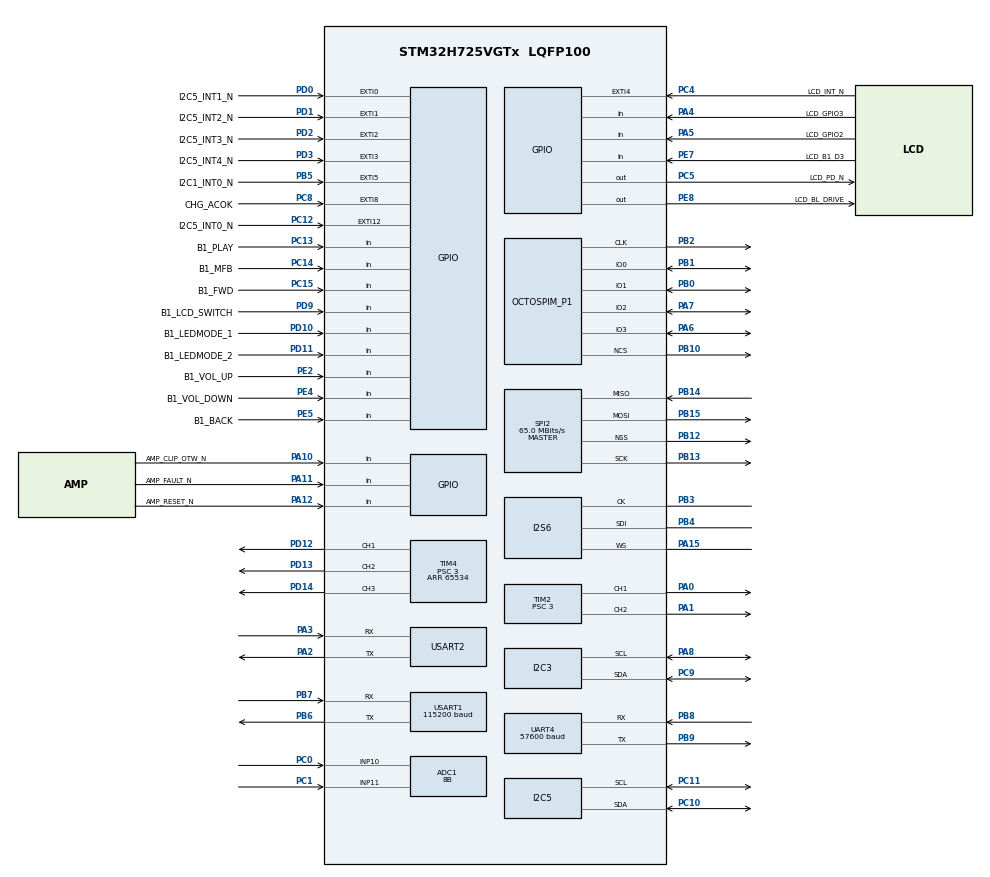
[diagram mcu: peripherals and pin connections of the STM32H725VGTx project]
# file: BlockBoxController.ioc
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ADC1.Channel-0\#ChannelRegularConversion=ADC_CHANNEL_10
ADC1.NbrOfConversion=1
ADC1.NbrOfConversionFlag=1
ADC1.OffsetNumber-0\#ChannelRegularConversion=ADC_OFFSET_NONE
ADC1.OffsetSignedSaturation-0\#ChannelRegularConversion=DISABLE
ADC1.OversamplingMode=ENABLE
ADC1.Rank-0\#ChannelRegularConversion=1
ADC1.Ratio=256
ADC1.Resolution=ADC_RESOLUTION_8B
ADC1.SamplingTime-0\#ChannelRegularConversion=ADC_SAMPLETIME_64CYCLES_5
ADC1.master=1
CORTEX_M7.AccessPermission-Cortex_Memory_Protection_Unit_Region0_Settings=MPU_REGION_FULL_ACCESS
CORTEX_M7.AccessPermission-Cortex_Memory_Protection_Unit_Region1_Settings=MPU_REGION_FULL_ACCESS
CORTEX_M7.AccessPermission-Cortex_Memory_Protection_Unit_Region2_Settings=MPU_REGION_FULL_ACCESS
CORTEX_M7.AccessPermission-Cortex_Memory_Protection_Unit_Region3_Settings=MPU_REGION_PRIV_RO_URO
CORTEX_M7.AccessPermission-Cortex_Memory_Protection_Unit_Region5_Settings=MPU_REGION_FULL_ACCESS
CORTEX_M7.BaseAddress-Cortex_Memory_Protection_Unit_Region1_Settings=0x90000000
CORTEX_M7.BaseAddress-Cortex_Memory_Protection_Unit_Region5_Settings=0x40000000
CORTEX_M7.CPU_ICache=Enabled
CORTEX_M7.DisableExec-Cortex_Memory_Protection_Unit_Region1_Settings=MPU_INSTRUCTION_ACCESS_DISABLE
CORTEX_M7.DisableExec-Cortex_Memory_Protection_Unit_Region4_Settings=MPU_INSTRUCTION_ACCESS_DISABLE
CORTEX_M7.DisableExec-Cortex_Memory_Protection_Unit_Region5_Settings=MPU_INSTRUCTION_ACCESS_DISABLE
CORTEX_M7.Enable-Cortex_Memory_Protection_Unit_Region0_Settings=MPU_REGION_ENABLE
CORTEX_M7.Enable-Cortex_Memory_Protection_Unit_Region1_Settings=MPU_REGION_ENABLE
CORTEX_M7.Enable-Cortex_Memory_Protection_Unit_Region2_Settings=MPU_REGION_ENABLE
CORTEX_M7.Enable-Cortex_Memory_Protection_Unit_Region3_Settings=MPU_REGION_ENABLE
CORTEX_M7.Enable-Cortex_Memory_Protection_Unit_Region4_Settings=MPU_REGION_ENABLE
CORTEX_M7.Enable-Cortex_Memory_Protection_Unit_Region5_Settings=MPU_REGION_ENABLE
CORTEX_M7.IsCacheable-Cortex_Memory_Protection_Unit_Region2_Settings=MPU_ACCESS_CACHEABLE
CORTEX_M7.IsCacheable-Cortex_Memory_Protection_Unit_Region3_Settings=MPU_ACCESS_CACHEABLE
CORTEX_M7.MPU_Control=MPU_PRIVILEGED_DEFAULT
CORTEX_M7.Size-Cortex_Memory_Protection_Unit_Region0_Settings=MPU_REGION_SIZE_4GB
CORTEX_M7.Size-Cortex_Memory_Protection_Unit_Region1_Settings=MPU_REGION_SIZE_256MB
CORTEX_M7.Size-Cortex_Memory_Protection_Unit_Region2_Settings=MPU_REGION_SIZE_512MB
CORTEX_M7.Size-Cortex_Memory_Protection_Unit_Region3_Settings=MPU_REGION_SIZE_64KB
CORTEX_M7.Size-Cortex_Memory_Protection_Unit_Region4_Settings=MPU_REGION_SIZE_4KB
CORTEX_M7.Size-Cortex_Memory_Protection_Unit_Region5_Settings=MPU_REGION_SIZE_512MB
CORTEX_M7.TypeExtField-Cortex_Memory_Protection_Unit_Region0_Settings=MPU_TEX_LEVEL1
CORTEX_M7.TypeExtField-Cortex_Memory_Protection_Unit_Region1_Settings=MPU_TEX_LEVEL2
CORTEX_M7.TypeExtField-Cortex_Memory_Protection_Unit_Region5_Settings=MPU_TEX_LEVEL2
I2C3.Timing=0x2000090E
I2C5.Timing=0x2000090E
I2S6.AudioFreq=I2S_AUDIOFREQ_96K
I2S6.DataFormat=I2S_DATAFORMAT_16B_EXTENDED
I2S6.ErrorAudioFreq=0.0 %
I2S6.Instance=SPI$Index
I2S6.RealAudioFreq=96.0 KHz
IWDG1.Prescaler=IWDG_PRESCALER_8
Mcu.Family=STM32H7
Mcu.Name=STM32H725VGTx
Mcu.Package=LQFP100
NVIC.ADC_IRQn=true\:13\:0\:true\:false\:true\:true\:true\:true
NVIC.EXTI0_IRQn=true\:6\:0\:true\:false\:true\:true\:true\:true
NVIC.EXTI15_10_IRQn=true\:10\:0\:true\:false\:true\:true\:true\:true
NVIC.EXTI1_IRQn=true\:7\:0\:true\:false\:true\:true\:true\:true
NVIC.EXTI2_IRQn=true\:8\:0\:true\:false\:true\:true\:true\:true
NVIC.EXTI3_IRQn=true\:9\:0\:true\:false\:true\:true\:true\:true
NVIC.I2C3_ER_IRQn=true\:13\:0\:true\:false\:true\:true\:true\:true
NVIC.I2C3_EV_IRQn=true\:13\:0\:true\:false\:true\:true\:true\:true
NVIC.I2C5_ER_IRQn=true\:12\:0\:true\:false\:true\:true\:true\:true
NVIC.I2C5_EV_IRQn=true\:12\:0\:true\:false\:true\:true\:true\:true
NVIC.PriorityGroup=NVIC_PRIORITYGROUP_4
NVIC.UART4_IRQn=true\:11\:0\:true\:false\:true\:true\:true\:true
NVIC.USART1_IRQn=true\:12\:0\:true\:false\:true\:true\:true\:true
NVIC.USART2_IRQn=true\:14\:0\:true\:false\:true\:true\:true\:true
OCTOSPI1.ChipSelectHighTime=8
OCTOSPI1.ClockPrescaler=26
OCTOSPI1.DeviceSize=24
OCTOSPI1.MemoryType=HAL_OSPI_MEMTYPE_APMEMORY
PA0.GPIO_PuPd=GPIO_PULLDOWN
PA0.Signal=S_TIM2_CH1_ETR
PA1.GPIO_PuPd=GPIO_PULLDOWN
PA1.Signal=S_TIM2_CH2
PA10.GPIO_Label=AMP_CLIP_OTW_N
PA10.GPIO_PuPd=GPIO_PULLUP
PA10.Signal=GPIO_Input
PA11.GPIO_Label=AMP_FAULT_N
PA11.GPIO_PuPd=GPIO_PULLUP
PA11.Signal=GPIO_Input
PA12.GPIO_Label=AMP_RESET_N
PA12.GPIO_PuPd=GPIO_PULLUP
PA12.Signal=GPIO_Input
PA13(JTMS/SWDIO).Mode=Serial_Wire
PA13(JTMS/SWDIO).Signal=DEBUG_JTMS-SWDIO
PA14(JTCK/SWCLK).Mode=Serial_Wire
PA14(JTCK/SWCLK).Signal=DEBUG_JTCK-SWCLK
PA15(JTDI).Mode=Half_Duplex_Slave_Rx
PA15(JTDI).Signal=I2S6_WS
PA2.Mode=Asynchronous
PA2.Signal=USART2_TX
PA3.Mode=Asynchronous
PA3.Signal=USART2_RX
PA4.GPIO_Label=LCD_GPIO3
PA4.GPIO_PuPd=GPIO_PULLDOWN
PA4.Signal=GPIO_Input
PA5.GPIO_Label=LCD_GPIO2
PA5.GPIO_PuPd=GPIO_PULLDOWN
PA5.Signal=GPIO_Input
PA6.GPIO_PuPd=GPIO_PULLUP
PA6.Mode=OCTOSPI1_IOL_Port1L
PA6.Signal=OCTOSPIM_P1_IO3
PA7.GPIO_PuPd=GPIO_PULLUP
PA7.Mode=OCTOSPI1_IOL_Port1L
PA7.Signal=OCTOSPIM_P1_IO2
PA8.Mode=I2C
PA8.Signal=I2C3_SCL
PB0.GPIO_PuPd=GPIO_PULLUP
PB0.Mode=OCTOSPI1_IOL_Port1L
PB0.Signal=OCTOSPIM_P1_IO1
PB1.GPIO_PuPd=GPIO_PULLUP
PB1.Mode=OCTOSPI1_IOL_Port1L
PB1.Signal=OCTOSPIM_P1_IO0
PB10.Mode=OCTOSPI1_Port1_NCS
PB10.Signal=OCTOSPIM_P1_NCS
PB12.GPIO_Speed=GPIO_SPEED_FREQ_HIGH
PB12.Mode=NSS_Signal_Hard_Output
PB12.Signal=SPI2_NSS
PB13.GPIO_Speed=GPIO_SPEED_FREQ_HIGH
PB13.Mode=Full_Duplex_Master
PB13.Signal=SPI2_SCK
PB14.GPIO_Speed=GPIO_SPEED_FREQ_HIGH
PB14.Mode=Full_Duplex_Master
PB14.Signal=SPI2_MISO
PB15.GPIO_Speed=GPIO_SPEED_FREQ_HIGH
PB15.Mode=Full_Duplex_Master
PB15.Signal=SPI2_MOSI
PB2.Mode=O1_P1_CLK
PB2.Signal=OCTOSPIM_P1_CLK
PB3(JTDO/TRACESWO).Mode=Half_Duplex_Slave_Rx
PB3(JTDO/TRACESWO).Signal=I2S6_CK
PB4(NJTRST).Mode=Half_Duplex_Slave_Rx
PB4(NJTRST).Signal=I2S6_SDI
PB5.GPIO_Label=I2C1_INT0_N
PB5.GPIO_ModeDefaultEXTI=GPIO_MODE_IT_FALLING
PB5.GPIO_PuPd=GPIO_PULLUP
PB5.Signal=GPXTI5
PB6.Mode=Asynchronous
PB6.Signal=USART1_TX
PB7.Mode=Asynchronous
PB7.Signal=USART1_RX
PB8.Mode=Asynchronous
PB8.Signal=UART4_RX
PB9.Mode=Asynchronous
PB9.Signal=UART4_TX
PC0.Signal=ADCx_INP10
PC1.Signal=ADCx_INP11
PC10.Mode=I2C
PC10.Signal=I2C5_SDA
PC11.Mode=I2C
PC11.Signal=I2C5_SCL
PC12.GPIO_Label=I2C5_INT0_N
PC12.GPIO_ModeDefaultEXTI=GPIO_MODE_IT_FALLING
PC12.GPIO_PuPd=GPIO_PULLUP
PC12.Signal=GPXTI12
PC13.GPIO_Label=B1_PLAY
PC13.GPIO_PuPd=GPIO_PULLUP
PC13.Signal=GPIO_Input
PC14-OSC32_IN.GPIO_Label=B1_MFB
PC14-OSC32_IN.GPIO_PuPd=GPIO_PULLUP
PC14-OSC32_IN.Signal=GPIO_Input
PC15-OSC32_OUT.GPIO_Label=B1_FWD
PC15-OSC32_OUT.GPIO_PuPd=GPIO_PULLUP
PC15-OSC32_OUT.Signal=GPIO_Input
PC4.GPIO_Label=LCD_INT_N
PC4.GPIO_ModeDefaultEXTI=GPIO_MODE_IT_FALLING
PC4.GPIO_PuPd=GPIO_PULLUP
PC4.Signal=GPXTI4
PC5.GPIO_Label=LCD_PD_N
PC5.Signal=GPIO_Output
PC8.GPIO_Label=CHG_ACOK
PC8.GPIO_ModeDefaultEXTI=GPIO_MODE_IT_RISING_FALLING
PC8.GPIO_PuPd=GPIO_PULLDOWN
PC8.Signal=GPXTI8
PC9.Mode=I2C
PC9.Signal=I2C3_SDA
PD0.GPIO_Label=I2C5_INT1_N
PD0.GPIO_ModeDefaultEXTI=GPIO_MODE_IT_FALLING
PD0.GPIO_PuPd=GPIO_PULLUP
PD0.Signal=GPXTI0
PD1.GPIO_Label=I2C5_INT2_N
PD1.GPIO_ModeDefaultEXTI=GPIO_MODE_IT_FALLING
PD1.GPIO_PuPd=GPIO_PULLUP
PD1.Signal=GPXTI1
PD10.GPIO_Label=B1_LEDMODE_1
PD10.GPIO_PuPd=GPIO_PULLUP
PD10.Signal=GPIO_Input
PD11.GPIO_Label=B1_LEDMODE_2
PD11.GPIO_PuPd=GPIO_PULLUP
PD11.Signal=GPIO_Input
PD12.GPIO_PuPd=GPIO_PULLDOWN
PD12.Signal=S_TIM4_CH1
PD13.GPIO_PuPd=GPIO_PULLDOWN
PD13.Signal=S_TIM4_CH2
PD14.GPIO_PuPd=GPIO_PULLDOWN
PD14.Signal=S_TIM4_CH3
PD2.GPIO_Label=I2C5_INT3_N
PD2.GPIO_ModeDefaultEXTI=GPIO_MODE_IT_FALLING
PD2.GPIO_PuPd=GPIO_PULLUP
PD2.Signal=GPXTI2
PD3.GPIO_Label=I2C5_INT4_N
PD3.GPIO_ModeDefaultEXTI=GPIO_MODE_IT_FALLING
PD3.GPIO_PuPd=GPIO_PULLUP
PD3.Signal=GPXTI3
PD9.GPIO_Label=B1_LCD_SWITCH
PD9.GPIO_PuPd=GPIO_PULLUP
PD9.Signal=GPIO_Input
PE2.GPIO_Label=B1_VOL_UP
PE2.GPIO_PuPd=GPIO_PULLUP
PE2.Signal=GPIO_Input
PE4.GPIO_Label=B1_VOL_DOWN
PE4.GPIO_PuPd=GPIO_PULLUP
PE4.Signal=GPIO_Input
PE5.GPIO_Label=B1_BACK
PE5.GPIO_PuPd=GPIO_PULLUP
PE5.Signal=GPIO_Input
PE7.GPIO_Label=LCD_B1_D3
PE7.GPIO_PuPd=GPIO_PULLDOWN
PE7.Signal=GPIO_Input
PE8.GPIO_Label=LCD_BL_DRIVE
PE8.PinState=GPIO_PIN_SET
PE8.Signal=GPIO_Output
ProjectManager.HeapSize=0x10000
ProjectManager.StackSize=0x1000
ProjectManager.TargetToolchain=STM32CubeIDE
RAMECC.Instance-RAMECC1_Monitor1=RAMECC1_Monitor1
RAMECC.Instance-RAMECC1_Monitor2=RAMECC1_Monitor2
RAMECC.Instance-RAMECC1_Monitor3=RAMECC1_Monitor3
RAMECC.Instance-RAMECC1_Monitor4=RAMECC1_Monitor4
RAMECC.Instance-RAMECC1_Monitor6=RAMECC1_Monitor6
RAMECC.Instance-RAMECC2_Monitor1=RAMECC2_Monitor1
RAMECC.Instance-RAMECC2_Monitor2_1=RAMECC2_Monitor2
RAMECC.Instance-RAMECC3_Monitor1=RAMECC3_Monitor1
RCC.ADCCLockSelection=RCC_ADCCLKSOURCE_PLL3
RCC.ADCFreq_Value=8000000
RCC.APB1Freq_Value=130000000
RCC.APB2Freq_Value=130000000
RCC.APB3Freq_Value=130000000
RCC.APB4Freq_Value=130000000
RCC.CortexFreq_Value=520000000
RCC.D1PPRE=RCC_APB3_DIV2
RCC.D2PPRE1=RCC_APB1_DIV2
RCC.D2PPRE2=RCC_APB2_DIV2
RCC.D3PPRE=RCC_APB4_DIV2
RCC.DIVM1=4
RCC.DIVM2=25
RCC.DIVN1=32
RCC.DIVN2=96
RCC.DIVN3=128
RCC.DIVP1=1
RCC.DIVQ1=4
RCC.DIVQ2=10
RCC.DIVR3=32
RCC.HCLKFreq_Value=260000000
RCC.HPRE=RCC_HCLK_DIV2
RCC.I2C123CLockSelection=RCC_I2C1235CLKSOURCE_PLL3
RCC.PLL2FRACN=0
RCC.PLL3FRACN=0
RCC.PLLFRACN=4096
RCC.PWR_Regulator_Voltage_Scale=PWR_REGULATOR_VOLTAGE_SCALE0
RCC.SPI6CLockSelection=RCC_SPI6CLKSOURCE_PLL2
RCC.SYSCLKFreq_VALUE=520000000
RCC.SYSCLKSource=RCC_SYSCLKSOURCE_PLLCLK
RCC.USBFreq_Value=130000000
SH.ADCx_INP10.0=ADC1_INP10,IN10-Single-Ended
SH.ADCx_INP11.0=ADC1_INP11,IN11-Single-Ended
SH.S_TIM2_CH1_ETR.0=TIM2_CH1,PWM Generation1 CH1
SH.S_TIM2_CH2.0=TIM2_CH2,PWM Generation2 CH2
SH.S_TIM4_CH1.0=TIM4_CH1,PWM Generation1 CH1
SH.S_TIM4_CH2.0=TIM4_CH2,PWM Generation2 CH2
SH.S_TIM4_CH3.0=TIM4_CH3,PWM Generation3 CH3
SPI2.CalculateBaudRate=65.0 MBits/s
SPI2.DataSize=SPI_DATASIZE_8BIT
SPI2.Direction=SPI_DIRECTION_2LINES
SPI2.Mode=SPI_MODE_MASTER
SPI2.VirtualNSS=VM_NSSHARD
SPI2.VirtualType=VM_MASTER
TIM2.Channel-PWM\ Generation1\ CH1=TIM_CHANNEL_1
TIM2.Channel-PWM\ Generation2\ CH2=TIM_CHANNEL_2
TIM2.Period=65535
TIM2.Prescaler=3
TIM4.Channel-PWM\ Generation1\ CH1=TIM_CHANNEL_1
TIM4.Channel-PWM\ Generation2\ CH2=TIM_CHANNEL_2
TIM4.Channel-PWM\ Generation3\ CH3=TIM_CHANNEL_3
TIM4.Channel-PWM\ Generation4\ No\ Output=TIM_CHANNEL_4
TIM4.OCMode_PWM-PWM\ Generation1\ CH1=TIM_OCMODE_PWM1
TIM4.OCMode_PWM-PWM\ Generation2\ CH2=TIM_OCMODE_PWM1
TIM4.OCMode_PWM-PWM\ Generation3\ CH3=TIM_OCMODE_COMBINED_PWM2
TIM4.OCMode_PWM-PWM\ Generation4\ No\ Output=TIM_OCMODE_COMBINED_PWM1
TIM4.OCPolarity_2=TIM_OCPOLARITY_LOW
TIM4.Period=65534
TIM4.Prescaler=3
TIM4.Pulse-PWM\ Generation2\ CH2=65535
TIM4.Pulse-PWM\ Generation3\ CH3=65535
UART4.BaudRate=57600
USART1.BaudRate=115200
USART1.VirtualMode-Asynchronous=VM_ASYNC
USART2.VirtualMode-Asynchronous=VM_ASYNC
VP_IWDG1_VS_IWDG.Mode=IWDG_Activate
VP_OCTOSPI1_VS_quad.Mode=quad_mode
VP_RAMECC_VS_D1_1.Mode=RAMECC1_Monitor1
VP_RAMECC_VS_D1_2.Mode=RAMECC1_Monitor2
VP_RAMECC_VS_D1_3.Mode=RAMECC1_Monitor3
VP_RAMECC_VS_D1_4.Mode=RAMECC1_Monitor4
VP_RAMECC_VS_D1_6.Mode=RAMECC1_Monitor6
VP_RAMECC_VS_D2_1.Mode=RAMECC2_Monitor1
VP_RAMECC_VS_D2_2.Mode=RAMECC2_Monitor2_1
VP_RAMECC_VS_D3_1.Mode=RAMECC3_Monitor1
VP_TIM4_VS_no_output4.Mode=PWM Generation4 No Output
board=custom

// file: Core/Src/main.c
/* USER CODE BEGIN Header */
/**
  ******************************************************************************
  * @file           : main.cpp
  * @brief          : Main program body
  ******************************************************************************
  * @attention
  *
  * Copyright (c) 2025 STMicroelectronics.
  * All rights reserved.
  *
  * This software is licensed under terms that can be found in the LICENSE file
  * in the root directory of this software component.
  * If no LICENSE file comes with this software, it is provided AS-IS.
  *
  ******************************************************************************
  */
/* USER CODE END Header */
#include "main.h"

/* USER CODE BEGIN Includes */
#include "cpp_main.h"
/* USER CODE END Includes */

ADC_HandleTypeDef hadc1;

I2C_HandleTypeDef hi2c3;
I2C_HandleTypeDef hi2c5;

I2S_HandleTypeDef hi2s6;

IWDG_HandleTypeDef hiwdg1;

OSPI_HandleTypeDef hospi1;

RAMECC_HandleTypeDef hramecc1_m1;
RAMECC_HandleTypeDef hramecc1_m2;
RAMECC_HandleTypeDef hramecc1_m3;
RAMECC_HandleTypeDef hramecc1_m4;
RAMECC_HandleTypeDef hramecc1_m6;
RAMECC_HandleTypeDef hramecc2_m1;
RAMECC_HandleTypeDef hramecc2_m2;
RAMECC_HandleTypeDef hramecc3_m1;

SPI_HandleTypeDef hspi2;

TIM_HandleTypeDef htim2;
TIM_HandleTypeDef htim4;

UART_HandleTypeDef huart4;
UART_HandleTypeDef huart1;
UART_HandleTypeDef huart2;

void SystemClock_Config(void);
void PeriphCommonClock_Config(void);
static void MPU_Config(void);
static void MX_GPIO_Init(void);
static void MX_I2C3_Init(void);
static void MX_I2C5_Init(void);
static void MX_OCTOSPI1_Init(void);
static void MX_SPI2_Init(void);
static void MX_TIM4_Init(void);
static void MX_I2S6_Init(void);
static void MX_TIM2_Init(void);
static void MX_USART2_UART_Init(void);
static void MX_ADC1_Init(void);
static void MX_UART4_Init(void);
static void MX_USART1_UART_Init(void);
static void MX_RAMECC_Init(void);
static void MX_IWDG1_Init(void);

int main(void)
{

  /* MPU Configuration--------------------------------------------------------*/
  MPU_Config();

  /* Enable I-Cache---------------------------------------------------------*/
  SCB_EnableICache();

  /* MCU Configuration--------------------------------------------------------*/

  /* Reset of all peripherals, Initializes the Flash interface and the Systick. */
  HAL_Init();

  /* Configure the system clock */
  SystemClock_Config();

/* Configure the peripherals common clocks */
  PeriphCommonClock_Config();

  /* Initialize all configured peripherals */
  MX_GPIO_Init();
  MX_I2C3_Init();
  MX_I2C5_Init();
  MX_OCTOSPI1_Init();
  MX_SPI2_Init();
  MX_TIM4_Init();
  MX_I2S6_Init();
  MX_TIM2_Init();
  MX_USART2_UART_Init();
  MX_ADC1_Init();
  MX_UART4_Init();
  MX_USART1_UART_Init();
  MX_RAMECC_Init();
  MX_IWDG1_Init();
  /* USER CODE BEGIN 2 */

  cpp_main();

  /* USER CODE END 2 */

  /* Infinite loop */
  while (1)
  {

  }
}

void SystemClock_Config(void)
{
  RCC_OscInitTypeDef RCC_OscInitStruct = {0};
  RCC_ClkInitTypeDef RCC_ClkInitStruct = {0};

  /** Supply configuration update enable
  */
  HAL_PWREx_ConfigSupply(PWR_DIRECT_SMPS_SUPPLY);

  /** Configure the main internal regulator output voltage
  */
  __HAL_PWR_VOLTAGESCALING_CONFIG(PWR_REGULATOR_VOLTAGE_SCALE0);

  while(!__HAL_PWR_GET_FLAG(PWR_FLAG_VOSRDY)) {}

  /** Initializes the RCC Oscillators according to the specified parameters
  * in the RCC_OscInitTypeDef structure.
  */
  RCC_OscInitStruct.OscillatorType = RCC_OSCILLATORTYPE_HSI|RCC_OSCILLATORTYPE_LSI;
  RCC_OscInitStruct.HSIState = RCC_HSI_DIV1;
  RCC_OscInitStruct.HSICalibrationValue = 64;
  RCC_OscInitStruct.LSIState = RCC_LSI_ON;
  RCC_OscInitStruct.PLL.PLLState = RCC_PLL_ON;
  RCC_OscInitStruct.PLL.PLLSource = RCC_PLLSOURCE_HSI;
  RCC_OscInitStruct.PLL.PLLM = 4;
  RCC_OscInitStruct.PLL.PLLN = 32;
  RCC_OscInitStruct.PLL.PLLP = 1;
  RCC_OscInitStruct.PLL.PLLQ = 4;
  RCC_OscInitStruct.PLL.PLLR = 2;
  RCC_OscInitStruct.PLL.PLLRGE = RCC_PLL1VCIRANGE_3;
  RCC_OscInitStruct.PLL.PLLVCOSEL = RCC_PLL1VCOWIDE;
  RCC_OscInitStruct.PLL.PLLFRACN = 4096;
  if (HAL_RCC_OscConfig(&RCC_OscInitStruct) != HAL_OK)
  {
    Error_Handler();
  }

  /** Initializes the CPU, AHB and APB buses clocks
  */
  RCC_ClkInitStruct.ClockType = RCC_CLOCKTYPE_HCLK|RCC_CLOCKTYPE_SYSCLK
                              |RCC_CLOCKTYPE_PCLK1|RCC_CLOCKTYPE_PCLK2
                              |RCC_CLOCKTYPE_D3PCLK1|RCC_CLOCKTYPE_D1PCLK1;
  RCC_ClkInitStruct.SYSCLKSource = RCC_SYSCLKSOURCE_PLLCLK;
  RCC_ClkInitStruct.SYSCLKDivider = RCC_SYSCLK_DIV1;
  RCC_ClkInitStruct.AHBCLKDivider = RCC_HCLK_DIV2;
  RCC_ClkInitStruct.APB3CLKDivider = RCC_APB3_DIV2;
  RCC_ClkInitStruct.APB1CLKDivider = RCC_APB1_DIV2;
  RCC_ClkInitStruct.APB2CLKDivider = RCC_APB2_DIV2;
  RCC_ClkInitStruct.APB4CLKDivider = RCC_APB4_DIV2;

  if (HAL_RCC_ClockConfig(&RCC_ClkInitStruct, FLASH_LATENCY_3) != HAL_OK)
  {
    Error_Handler();
  }
}

void PeriphCommonClock_Config(void)
{
  RCC_PeriphCLKInitTypeDef PeriphClkInitStruct = {0};

  /** Initializes the peripherals clock
  */
  PeriphClkInitStruct.PeriphClockSelection = RCC_PERIPHCLK_ADC|RCC_PERIPHCLK_I2C3
                              |RCC_PERIPHCLK_I2C5;
  PeriphClkInitStruct.PLL3.PLL3M = 32;
  PeriphClkInitStruct.PLL3.PLL3N = 128;
  PeriphClkInitStruct.PLL3.PLL3P = 2;
  PeriphClkInitStruct.PLL3.PLL3Q = 2;
  PeriphClkInitStruct.PLL3.PLL3R = 32;
  PeriphClkInitStruct.PLL3.PLL3RGE = RCC_PLL3VCIRANGE_1;
  PeriphClkInitStruct.PLL3.PLL3VCOSEL = RCC_PLL3VCOWIDE;
  PeriphClkInitStruct.PLL3.PLL3FRACN = 0;
  PeriphClkInitStruct.I2c123ClockSelection = RCC_I2C1235CLKSOURCE_PLL3;
  PeriphClkInitStruct.AdcClockSelection = RCC_ADCCLKSOURCE_PLL3;
  if (HAL_RCCEx_PeriphCLKConfig(&PeriphClkInitStruct) != HAL_OK)
  {
    Error_Handler();
  }
}

static void MX_ADC1_Init(void)
{

  ADC_MultiModeTypeDef multimode = {0};
  ADC_ChannelConfTypeDef sConfig = {0};

  /** Common config
  */
  hadc1.Instance = ADC1;
  hadc1.Init.ClockPrescaler = ADC_CLOCK_ASYNC_DIV1;
  hadc1.Init.Resolution = ADC_RESOLUTION_8B;
  hadc1.Init.ScanConvMode = ADC_SCAN_DISABLE;
  hadc1.Init.EOCSelection = ADC_EOC_SINGLE_CONV;
  hadc1.Init.LowPowerAutoWait = DISABLE;
  hadc1.Init.ContinuousConvMode = DISABLE;
  hadc1.Init.NbrOfConversion = 1;
  hadc1.Init.DiscontinuousConvMode = DISABLE;
  hadc1.Init.ExternalTrigConv = ADC_SOFTWARE_START;
  hadc1.Init.ExternalTrigConvEdge = ADC_EXTERNALTRIGCONVEDGE_NONE;
  hadc1.Init.ConversionDataManagement = ADC_CONVERSIONDATA_DR;
  hadc1.Init.Overrun = ADC_OVR_DATA_PRESERVED;
  hadc1.Init.LeftBitShift = ADC_LEFTBITSHIFT_NONE;
  hadc1.Init.OversamplingMode = ENABLE;
  hadc1.Init.Oversampling.Ratio = 256;
  hadc1.Init.Oversampling.RightBitShift = ADC_RIGHTBITSHIFT_NONE;
  hadc1.Init.Oversampling.TriggeredMode = ADC_TRIGGEREDMODE_SINGLE_TRIGGER;
  hadc1.Init.Oversampling.OversamplingStopReset = ADC_REGOVERSAMPLING_CONTINUED_MODE;
  if (HAL_ADC_Init(&hadc1) != HAL_OK)
  {
    Error_Handler();
  }

  /** Configure the ADC multi-mode
  */
  multimode.Mode = ADC_MODE_INDEPENDENT;
  if (HAL_ADCEx_MultiModeConfigChannel(&hadc1, &multimode) != HAL_OK)
  {
    Error_Handler();
  }

  /** Configure Regular Channel
  */
  sConfig.Channel = ADC_CHANNEL_10;
  sConfig.Rank = ADC_REGULAR_RANK_1;
  sConfig.SamplingTime = ADC_SAMPLETIME_64CYCLES_5;
  sConfig.SingleDiff = ADC_SINGLE_ENDED;
  sConfig.OffsetNumber = ADC_OFFSET_NONE;
  sConfig.Offset = 0;
  sConfig.OffsetSignedSaturation = DISABLE;
  if (HAL_ADC_ConfigChannel(&hadc1, &sConfig) != HAL_OK)
  {
    Error_Handler();
  }

}

static void MX_I2C3_Init(void)
{

  hi2c3.Instance = I2C3;
  hi2c3.Init.Timing = 0x2000090E;
  hi2c3.Init.OwnAddress1 = 0;
  hi2c3.Init.AddressingMode = I2C_ADDRESSINGMODE_7BIT;
  hi2c3.Init.DualAddressMode = I2C_DUALADDRESS_DISABLE;
  hi2c3.Init.OwnAddress2 = 0;
  hi2c3.Init.OwnAddress2Masks = I2C_OA2_NOMASK;
  hi2c3.Init.GeneralCallMode = I2C_GENERALCALL_DISABLE;
  hi2c3.Init.NoStretchMode = I2C_NOSTRETCH_DISABLE;
  if (HAL_I2C_Init(&hi2c3) != HAL_OK)
  {
    Error_Handler();
  }

  /** Configure Analogue filter
  */
  if (HAL_I2CEx_ConfigAnalogFilter(&hi2c3, I2C_ANALOGFILTER_ENABLE) != HAL_OK)
  {
    Error_Handler();
  }

  /** Configure Digital filter
  */
  if (HAL_I2CEx_ConfigDigitalFilter(&hi2c3, 0) != HAL_OK)
  {
    Error_Handler();
  }

}

static void MX_I2C5_Init(void)
{

  hi2c5.Instance = I2C5;
  hi2c5.Init.Timing = 0x2000090E;
  hi2c5.Init.OwnAddress1 = 0;
  hi2c5.Init.AddressingMode = I2C_ADDRESSINGMODE_7BIT;
  hi2c5.Init.DualAddressMode = I2C_DUALADDRESS_DISABLE;
  hi2c5.Init.OwnAddress2 = 0;
  hi2c5.Init.OwnAddress2Masks = I2C_OA2_NOMASK;
  hi2c5.Init.GeneralCallMode = I2C_GENERALCALL_DISABLE;
  hi2c5.Init.NoStretchMode = I2C_NOSTRETCH_DISABLE;
  if (HAL_I2C_Init(&hi2c5) != HAL_OK)
  {
    Error_Handler();
  }

  /** Configure Analogue filter
  */
  if (HAL_I2CEx_ConfigAnalogFilter(&hi2c5, I2C_ANALOGFILTER_ENABLE) != HAL_OK)
  {
    Error_Handler();
  }

  /** Configure Digital filter
  */
  if (HAL_I2CEx_ConfigDigitalFilter(&hi2c5, 0) != HAL_OK)
  {
    Error_Handler();
  }

}

static void MX_I2S6_Init(void)
{

  hi2s6.Instance = SPI6;
  hi2s6.Init.Mode = I2S_MODE_SLAVE_RX;
  hi2s6.Init.Standard = I2S_STANDARD_PHILIPS;
  hi2s6.Init.DataFormat = I2S_DATAFORMAT_16B_EXTENDED;
  hi2s6.Init.MCLKOutput = I2S_MCLKOUTPUT_DISABLE;
  hi2s6.Init.AudioFreq = I2S_AUDIOFREQ_96K;
  hi2s6.Init.CPOL = I2S_CPOL_LOW;
  hi2s6.Init.FirstBit = I2S_FIRSTBIT_MSB;
  hi2s6.Init.WSInversion = I2S_WS_INVERSION_DISABLE;
  hi2s6.Init.Data24BitAlignment = I2S_DATA_24BIT_ALIGNMENT_RIGHT;
  hi2s6.Init.MasterKeepIOState = I2S_MASTER_KEEP_IO_STATE_DISABLE;
  if (HAL_I2S_Init(&hi2s6) != HAL_OK)
  {
    Error_Handler();
  }

}

static void MX_IWDG1_Init(void)
{

  hiwdg1.Instance = IWDG1;
  hiwdg1.Init.Prescaler = IWDG_PRESCALER_8;
  hiwdg1.Init.Window = 4095;
  hiwdg1.Init.Reload = 4095;
  if (HAL_IWDG_Init(&hiwdg1) != HAL_OK)
  {
    Error_Handler();
  }

}

static void MX_OCTOSPI1_Init(void)
{

  OSPIM_CfgTypeDef sOspiManagerCfg = {0};

  /* OCTOSPI1 parameter configuration*/
  hospi1.Instance = OCTOSPI1;
  hospi1.Init.FifoThreshold = 1;
  hospi1.Init.DualQuad = HAL_OSPI_DUALQUAD_DISABLE;
  hospi1.Init.MemoryType = HAL_OSPI_MEMTYPE_APMEMORY;
  hospi1.Init.DeviceSize = 24;
  hospi1.Init.ChipSelectHighTime = 8;
  hospi1.Init.FreeRunningClock = HAL_OSPI_FREERUNCLK_DISABLE;
  hospi1.Init.ClockMode = HAL_OSPI_CLOCK_MODE_0;
  hospi1.Init.WrapSize = HAL_OSPI_WRAP_NOT_SUPPORTED;
  hospi1.Init.ClockPrescaler = 26;
  hospi1.Init.SampleShifting = HAL_OSPI_SAMPLE_SHIFTING_NONE;
  hospi1.Init.DelayHoldQuarterCycle = HAL_OSPI_DHQC_DISABLE;
  hospi1.Init.ChipSelectBoundary = 0;
  hospi1.Init.DelayBlockBypass = HAL_OSPI_DELAY_BLOCK_BYPASSED;
  hospi1.Init.MaxTran = 0;
  hospi1.Init.Refresh = 0;
  if (HAL_OSPI_Init(&hospi1) != HAL_OK)
  {
    Error_Handler();
  }
  sOspiManagerCfg.ClkPort = 1;
  sOspiManagerCfg.NCSPort = 1;
  sOspiManagerCfg.IOLowPort = HAL_OSPIM_IOPORT_1_LOW;
  if (HAL_OSPIM_Config(&hospi1, &sOspiManagerCfg, HAL_OSPI_TIMEOUT_DEFAULT_VALUE) != HAL_OK)
  {
    Error_Handler();
  }

}

static void MX_RAMECC_Init(void)
{

  /** Initialize RAMECC1 M1 : AXI SRAM
  */
  hramecc1_m1.Instance = RAMECC1_Monitor1;
  if (HAL_RAMECC_Init(&hramecc1_m1) != HAL_OK)
  {
    Error_Handler();
  }

  /** Initialize RAMECC1 M2 : ITCM-RAM
  */
  hramecc1_m2.Instance = RAMECC1_Monitor2;
  if (HAL_RAMECC_Init(&hramecc1_m2) != HAL_OK)
  {
    Error_Handler();
  }

  /** Initialize RAMECC1 M3 : D0TCM-RAM
  */
  hramecc1_m3.Instance = RAMECC1_Monitor3;
  if (HAL_RAMECC_Init(&hramecc1_m3) != HAL_OK)
  {
    Error_Handler();
  }

  /** Initialize RAMECC1 M4 : D1TCM-RAM
  */
  hramecc1_m4.Instance = RAMECC1_Monitor4;
  if (HAL_RAMECC_Init(&hramecc1_m4) != HAL_OK)
  {
    Error_Handler();
  }

  /** Initialize RAMECC1 M6 : SRAM
  */
  hramecc1_m6.Instance = RAMECC1_Monitor6;
  if (HAL_RAMECC_Init(&hramecc1_m6) != HAL_OK)
  {
    Error_Handler();
  }

  /** Initialize RAMECC2 M1 : SRAM1_0
  */
  hramecc2_m1.Instance = RAMECC2_Monitor1;
  if (HAL_RAMECC_Init(&hramecc2_m1) != HAL_OK)
  {
    Error_Handler();
  }

  /** Initialize RAMECC2 M2 : SRAM2_0
  */
  hramecc2_m2.Instance = RAMECC2_Monitor2;
  if (HAL_RAMECC_Init(&hramecc2_m2) != HAL_OK)
  {
    Error_Handler();
  }

  /** Initialize RAMECC3 M1 : SRAM4
  */
  hramecc3_m1.Instance = RAMECC3_Monitor1;
  if (HAL_RAMECC_Init(&hramecc3_m1) != HAL_OK)
  {
    Error_Handler();
  }
  /* USER CODE BEGIN RAMECC_Init 2 */
  HAL_RAMECC_EnableNotification(&hramecc1_m1, RAMECC_IT_MONITOR_ALL);
  HAL_RAMECC_EnableNotification(&hramecc1_m2, RAMECC_IT_MONITOR_ALL);
  HAL_RAMECC_EnableNotification(&hramecc1_m3, RAMECC_IT_MONITOR_ALL);
  HAL_RAMECC_EnableNotification(&hramecc1_m4, RAMECC_IT_MONITOR_ALL);
  HAL_RAMECC_EnableNotification(&hramecc1_m6, RAMECC_IT_MONITOR_ALL);
  //HAL_RAMECC_EnableNotification(&hramecc2_m1, RAMECC_IT_MONITOR_ALL);
  //HAL_RAMECC_EnableNotification(&hramecc2_m2, RAMECC_IT_MONITOR_ALL);
  //HAL_RAMECC_EnableNotification(&hramecc3_m1, RAMECC_IT_MONITOR_ALL);
  HAL_NVIC_SetPriority(ECC_IRQn, 1, 0);
  HAL_NVIC_EnableIRQ(ECC_IRQn);
  HAL_RAMECC_StartMonitor(&hramecc1_m1);
  HAL_RAMECC_StartMonitor(&hramecc1_m2);
  HAL_RAMECC_StartMonitor(&hramecc1_m3);
  HAL_RAMECC_StartMonitor(&hramecc1_m4);
  HAL_RAMECC_StartMonitor(&hramecc1_m6);
  //HAL_RAMECC_StartMonitor(&hramecc2_m1);
  //HAL_RAMECC_StartMonitor(&hramecc2_m2);
  //HAL_RAMECC_StartMonitor(&hramecc3_m1);
  /* USER CODE END RAMECC_Init 2 */

}

static void MX_SPI2_Init(void)
{

  /* SPI2 parameter configuration*/
  hspi2.Instance = SPI2;
  hspi2.Init.Mode = SPI_MODE_MASTER;
  hspi2.Init.Direction = SPI_DIRECTION_2LINES;
  hspi2.Init.DataSize = SPI_DATASIZE_8BIT;
  hspi2.Init.CLKPolarity = SPI_POLARITY_LOW;
  hspi2.Init.CLKPhase = SPI_PHASE_1EDGE;
  hspi2.Init.NSS = SPI_NSS_HARD_OUTPUT;
  hspi2.Init.BaudRatePrescaler = SPI_BAUDRATEPRESCALER_2;
  hspi2.Init.FirstBit = SPI_FIRSTBIT_MSB;
  hspi2.Init.TIMode = SPI_TIMODE_DISABLE;
  hspi2.Init.CRCCalculation = SPI_CRCCALCULATION_DISABLE;
  hspi2.Init.CRCPolynomial = 0x0;
  hspi2.Init.NSSPMode = SPI_NSS_PULSE_ENABLE;
  hspi2.Init.NSSPolarity = SPI_NSS_POLARITY_LOW;
  hspi2.Init.FifoThreshold = SPI_FIFO_THRESHOLD_01DATA;
  hspi2.Init.TxCRCInitializationPattern = SPI_CRC_INITIALIZATION_ALL_ZERO_PATTERN;
  hspi2.Init.RxCRCInitializationPattern = SPI_CRC_INITIALIZATION_ALL_ZERO_PATTERN;
  hspi2.Init.MasterSSIdleness = SPI_MASTER_SS_IDLENESS_00CYCLE;
  hspi2.Init.MasterInterDataIdleness = SPI_MASTER_INTERDATA_IDLENESS_00CYCLE;
  hspi2.Init.MasterReceiverAutoSusp = SPI_MASTER_RX_AUTOSUSP_DISABLE;
  hspi2.Init.MasterKeepIOState = SPI_MASTER_KEEP_IO_STATE_DISABLE;
  hspi2.Init.IOSwap = SPI_IO_SWAP_DISABLE;
  if (HAL_SPI_Init(&hspi2) != HAL_OK)
  {
    Error_Handler();
  }

}

static void MX_TIM2_Init(void)
{

  TIM_MasterConfigTypeDef sMasterConfig = {0};
  TIM_OC_InitTypeDef sConfigOC = {0};

  htim2.Instance = TIM2;
  htim2.Init.Prescaler = 3;
  htim2.Init.CounterMode = TIM_COUNTERMODE_UP;
  htim2.Init.Period = 65535;
  htim2.Init.ClockDivision = TIM_CLOCKDIVISION_DIV1;
  htim2.Init.AutoReloadPreload = TIM_AUTORELOAD_PRELOAD_DISABLE;
  if (HAL_TIM_PWM_Init(&htim2) != HAL_OK)
  {
    Error_Handler();
  }
  sMasterConfig.MasterOutputTrigger = TIM_TRGO_RESET;
  sMasterConfig.MasterSlaveMode = TIM_MASTERSLAVEMODE_DISABLE;
  if (HAL_TIMEx_MasterConfigSynchronization(&htim2, &sMasterConfig) != HAL_OK)
  {
    Error_Handler();
  }
  sConfigOC.OCMode = TIM_OCMODE_PWM1;
  sConfigOC.Pulse = 0;
  sConfigOC.OCPolarity = TIM_OCPOLARITY_HIGH;
  sConfigOC.OCFastMode = TIM_OCFAST_DISABLE;
  if (HAL_TIM_PWM_ConfigChannel(&htim2, &sConfigOC, TIM_CHANNEL_1) != HAL_OK)
  {
    Error_Handler();
  }
  if (HAL_TIM_PWM_ConfigChannel(&htim2, &sConfigOC, TIM_CHANNEL_2) != HAL_OK)
  {
    Error_Handler();
  }
  HAL_TIM_MspPostInit(&htim2);

}

static void MX_TIM4_Init(void)
{

  TIM_MasterConfigTypeDef sMasterConfig = {0};
  TIM_OC_InitTypeDef sConfigOC = {0};

  htim4.Instance = TIM4;
  htim4.Init.Prescaler = 3;
  htim4.Init.CounterMode = TIM_COUNTERMODE_UP;
  htim4.Init.Period = 65534;
  htim4.Init.ClockDivision = TIM_CLOCKDIVISION_DIV1;
  htim4.Init.AutoReloadPreload = TIM_AUTORELOAD_PRELOAD_DISABLE;
  if (HAL_TIM_PWM_Init(&htim4) != HAL_OK)
  {
    Error_Handler();
  }
  sMasterConfig.MasterOutputTrigger = TIM_TRGO_RESET;
  sMasterConfig.MasterSlaveMode = TIM_MASTERSLAVEMODE_DISABLE;
  if (HAL_TIMEx_MasterConfigSynchronization(&htim4, &sMasterConfig) != HAL_OK)
  {
    Error_Handler();
  }
  sConfigOC.OCMode = TIM_OCMODE_PWM1;
  sConfigOC.Pulse = 0;
  sConfigOC.OCPolarity = TIM_OCPOLARITY_HIGH;
  sConfigOC.OCFastMode = TIM_OCFAST_DISABLE;
  if (HAL_TIM_PWM_ConfigChannel(&htim4, &sConfigOC, TIM_CHANNEL_1) != HAL_OK)
  {
    Error_Handler();
  }
  sConfigOC.Pulse = 65535;
  sConfigOC.OCPolarity = TIM_OCPOLARITY_LOW;
  if (HAL_TIM_PWM_ConfigChannel(&htim4, &sConfigOC, TIM_CHANNEL_2) != HAL_OK)
  {
    Error_Handler();
  }
  sConfigOC.OCMode = TIM_OCMODE_COMBINED_PWM2;
  sConfigOC.OCPolarity = TIM_OCPOLARITY_HIGH;
  if (HAL_TIM_PWM_ConfigChannel(&htim4, &sConfigOC, TIM_CHANNEL_3) != HAL_OK)
  {
    Error_Handler();
  }
  sConfigOC.OCMode = TIM_OCMODE_COMBINED_PWM1;
  sConfigOC.Pulse = 0;
  if (HAL_TIM_PWM_ConfigChannel(&htim4, &sConfigOC, TIM_CHANNEL_4) != HAL_OK)
  {
    Error_Handler();
  }
  HAL_TIM_MspPostInit(&htim4);

}

static void MX_UART4_Init(void)
{

  huart4.Instance = UART4;
  huart4.Init.BaudRate = 57600;
  huart4.Init.WordLength = UART_WORDLENGTH_8B;
  huart4.Init.StopBits = UART_STOPBITS_1;
  huart4.Init.Parity = UART_PARITY_NONE;
  huart4.Init.Mode = UART_MODE_TX_RX;
  huart4.Init.HwFlowCtl = UART_HWCONTROL_NONE;
  huart4.Init.OverSampling = UART_OVERSAMPLING_16;
  huart4.Init.OneBitSampling = UART_ONE_BIT_SAMPLE_DISABLE;
  huart4.Init.ClockPrescaler = UART_PRESCALER_DIV1;
  huart4.AdvancedInit.AdvFeatureInit = UART_ADVFEATURE_NO_INIT;
  if (HAL_UART_Init(&huart4) != HAL_OK)
  {
    Error_Handler();
  }
  if (HAL_UARTEx_SetTxFifoThreshold(&huart4, UART_TXFIFO_THRESHOLD_1_8) != HAL_OK)
  {
    Error_Handler();
  }
  if (HAL_UARTEx_SetRxFifoThreshold(&huart4, UART_RXFIFO_THRESHOLD_1_8) != HAL_OK)
  {
    Error_Handler();
  }
  if (HAL_UARTEx_DisableFifoMode(&huart4) != HAL_OK)
  {
    Error_Handler();
  }

}

static void MX_USART1_UART_Init(void)
{

  huart1.Instance = USART1;
  huart1.Init.BaudRate = 115200;
  huart1.Init.WordLength = UART_WORDLENGTH_8B;
  huart1.Init.StopBits = UART_STOPBITS_1;
  huart1.Init.Parity = UART_PARITY_NONE;
  huart1.Init.Mode = UART_MODE_TX_RX;
  huart1.Init.HwFlowCtl = UART_HWCONTROL_NONE;
  huart1.Init.OverSampling = UART_OVERSAMPLING_16;
  huart1.Init.OneBitSampling = UART_ONE_BIT_SAMPLE_DISABLE;
  huart1.Init.ClockPrescaler = UART_PRESCALER_DIV1;
  huart1.AdvancedInit.AdvFeatureInit = UART_ADVFEATURE_NO_INIT;
  if (HAL_UART_Init(&huart1) != HAL_OK)
  {
    Error_Handler();
  }
  if (HAL_UARTEx_SetTxFifoThreshold(&huart1, UART_TXFIFO_THRESHOLD_1_8) != HAL_OK)
  {
    Error_Handler();
  }
  if (HAL_UARTEx_SetRxFifoThreshold(&huart1, UART_RXFIFO_THRESHOLD_1_8) != HAL_OK)
  {
    Error_Handler();
  }
  if (HAL_UARTEx_DisableFifoMode(&huart1) != HAL_OK)
  {
    Error_Handler();
  }

}

static void MX_USART2_UART_Init(void)
{

  huart2.Instance = USART2;
  huart2.Init.BaudRate = 115200;
  huart2.Init.WordLength = UART_WORDLENGTH_8B;
  huart2.Init.StopBits = UART_STOPBITS_1;
  huart2.Init.Parity = UART_PARITY_NONE;
  huart2.Init.Mode = UART_MODE_TX_RX;
  huart2.Init.HwFlowCtl = UART_HWCONTROL_NONE;
  huart2.Init.OverSampling = UART_OVERSAMPLING_16;
  huart2.Init.OneBitSampling = UART_ONE_BIT_SAMPLE_DISABLE;
  huart2.Init.ClockPrescaler = UART_PRESCALER_DIV1;
  huart2.AdvancedInit.AdvFeatureInit = UART_ADVFEATURE_NO_INIT;
  if (HAL_UART_Init(&huart2) != HAL_OK)
  {
    Error_Handler();
  }
  if (HAL_UARTEx_SetTxFifoThreshold(&huart2, UART_TXFIFO_THRESHOLD_1_8) != HAL_OK)
  {
    Error_Handler();
  }
  if (HAL_UARTEx_SetRxFifoThreshold(&huart2, UART_RXFIFO_THRESHOLD_1_8) != HAL_OK)
  {
    Error_Handler();
  }
  if (HAL_UARTEx_DisableFifoMode(&huart2) != HAL_OK)
  {
    Error_Handler();
  }

}

static void MX_GPIO_Init(void)
{
  GPIO_InitTypeDef GPIO_InitStruct = {0};

  /* GPIO Ports Clock Enable */
  __HAL_RCC_GPIOE_CLK_ENABLE();
  __HAL_RCC_GPIOC_CLK_ENABLE();
  __HAL_RCC_GPIOA_CLK_ENABLE();
  __HAL_RCC_GPIOB_CLK_ENABLE();
  __HAL_RCC_GPIOD_CLK_ENABLE();

  /*Configure GPIO pin Output Level */
  HAL_GPIO_WritePin(LCD_PD_N_GPIO_Port, LCD_PD_N_Pin, GPIO_PIN_RESET);

  /*Configure GPIO pin Output Level */
  HAL_GPIO_WritePin(LCD_BL_DRIVE_GPIO_Port, LCD_BL_DRIVE_Pin, GPIO_PIN_SET);

  /*Configure GPIO pins : B1_VOL_UP_Pin B1_VOL_DOWN_Pin B1_BACK_Pin */
  GPIO_InitStruct.Pin = B1_VOL_UP_Pin|B1_VOL_DOWN_Pin|B1_BACK_Pin;
  GPIO_InitStruct.Mode = GPIO_MODE_INPUT;
  GPIO_InitStruct.Pull = GPIO_PULLUP;
  HAL_GPIO_Init(GPIOE, &GPIO_InitStruct);

  /*Configure GPIO pins : B1_PLAY_Pin B1_MFB_Pin B1_FWD_Pin */
  GPIO_InitStruct.Pin = B1_PLAY_Pin|B1_MFB_Pin|B1_FWD_Pin;
  GPIO_InitStruct.Mode = GPIO_MODE_INPUT;
  GPIO_InitStruct.Pull = GPIO_PULLUP;
  HAL_GPIO_Init(GPIOC, &GPIO_InitStruct);

  /*Configure GPIO pins : LCD_GPIO3_Pin LCD_GPIO2_Pin */
  GPIO_InitStruct.Pin = LCD_GPIO3_Pin|LCD_GPIO2_Pin;
  GPIO_InitStruct.Mode = GPIO_MODE_INPUT;
  GPIO_InitStruct.Pull = GPIO_PULLDOWN;
  HAL_GPIO_Init(GPIOA, &GPIO_InitStruct);

  /*Configure GPIO pins : LCD_INT_N_Pin I2C5_INT0_N_Pin */
  GPIO_InitStruct.Pin = LCD_INT_N_Pin|I2C5_INT0_N_Pin;
  GPIO_InitStruct.Mode = GPIO_MODE_IT_FALLING;
  GPIO_InitStruct.Pull = GPIO_PULLUP;
  HAL_GPIO_Init(GPIOC, &GPIO_InitStruct);

  /*Configure GPIO pin : LCD_PD_N_Pin */
  GPIO_InitStruct.Pin = LCD_PD_N_Pin;
  GPIO_InitStruct.Mode = GPIO_MODE_OUTPUT_PP;
  GPIO_InitStruct.Pull = GPIO_NOPULL;
  GPIO_InitStruct.Speed = GPIO_SPEED_FREQ_LOW;
  HAL_GPIO_Init(LCD_PD_N_GPIO_Port, &GPIO_InitStruct);

  /*Configure GPIO pin : LCD_B1_D3_Pin */
  GPIO_InitStruct.Pin = LCD_B1_D3_Pin;
  GPIO_InitStruct.Mode = GPIO_MODE_INPUT;
  GPIO_InitStruct.Pull = GPIO_PULLDOWN;
  HAL_GPIO_Init(LCD_B1_D3_GPIO_Port, &GPIO_InitStruct);

  /*Configure GPIO pin : LCD_BL_DRIVE_Pin */
  GPIO_InitStruct.Pin = LCD_BL_DRIVE_Pin;
  GPIO_InitStruct.Mode = GPIO_MODE_OUTPUT_PP;
  GPIO_InitStruct.Pull = GPIO_NOPULL;
  GPIO_InitStruct.Speed = GPIO_SPEED_FREQ_LOW;
  HAL_GPIO_Init(LCD_BL_DRIVE_GPIO_Port, &GPIO_InitStruct);

  /*Configure GPIO pins : B1_LCD_SWITCH_Pin B1_LEDMODE_1_Pin B1_LEDMODE_2_Pin */
  GPIO_InitStruct.Pin = B1_LCD_SWITCH_Pin|B1_LEDMODE_1_Pin|B1_LEDMODE_2_Pin;
  GPIO_InitStruct.Mode = GPIO_MODE_INPUT;
  GPIO_InitStruct.Pull = GPIO_PULLUP;
  HAL_GPIO_Init(GPIOD, &GPIO_InitStruct);

  /*Configure GPIO pin : CHG_ACOK_Pin */
  GPIO_InitStruct.Pin = CHG_ACOK_Pin;
  GPIO_InitStruct.Mode = GPIO_MODE_IT_RISING_FALLING;
  GPIO_InitStruct.Pull = GPIO_PULLDOWN;
  HAL_GPIO_Init(CHG_ACOK_GPIO_Port, &GPIO_InitStruct);

  /*Configure GPIO pins : AMP_CLIP_OTW_N_Pin AMP_FAULT_N_Pin AMP_RESET_N_Pin */
  GPIO_InitStruct.Pin = AMP_CLIP_OTW_N_Pin|AMP_FAULT_N_Pin|AMP_RESET_N_Pin;
  GPIO_InitStruct.Mode = GPIO_MODE_INPUT;
  GPIO_InitStruct.Pull = GPIO_PULLUP;
  HAL_GPIO_Init(GPIOA, &GPIO_InitStruct);

  /*Configure GPIO pins : I2C5_INT1_N_Pin I2C5_INT2_N_Pin I2C5_INT3_N_Pin I2C5_INT4_N_Pin */
  GPIO_InitStruct.Pin = I2C5_INT1_N_Pin|I2C5_INT2_N_Pin|I2C5_INT3_N_Pin|I2C5_INT4_N_Pin;
  GPIO_InitStruct.Mode = GPIO_MODE_IT_FALLING;
  GPIO_InitStruct.Pull = GPIO_PULLUP;
  HAL_GPIO_Init(GPIOD, &GPIO_InitStruct);

  /*Configure GPIO pin : I2C1_INT0_N_Pin */
  GPIO_InitStruct.Pin = I2C1_INT0_N_Pin;
  GPIO_InitStruct.Mode = GPIO_MODE_IT_FALLING;
  GPIO_InitStruct.Pull = GPIO_PULLUP;
  HAL_GPIO_Init(I2C1_INT0_N_GPIO_Port, &GPIO_InitStruct);

  /* EXTI interrupt init*/
  HAL_NVIC_SetPriority(EXTI0_IRQn, 6, 0);
  HAL_NVIC_EnableIRQ(EXTI0_IRQn);

  HAL_NVIC_SetPriority(EXTI1_IRQn, 7, 0);
  HAL_NVIC_EnableIRQ(EXTI1_IRQn);

  HAL_NVIC_SetPriority(EXTI2_IRQn, 8, 0);
  HAL_NVIC_EnableIRQ(EXTI2_IRQn);

  HAL_NVIC_SetPriority(EXTI3_IRQn, 9, 0);
  HAL_NVIC_EnableIRQ(EXTI3_IRQn);

  HAL_NVIC_SetPriority(EXTI15_10_IRQn, 10, 0);
  HAL_NVIC_EnableIRQ(EXTI15_10_IRQn);

}

/* MPU Configuration */

void MPU_Config(void)
{
  MPU_Region_InitTypeDef MPU_InitStruct = {0};

  /* Disables the MPU */
  HAL_MPU_Disable();

  /** Initializes and configures the Region and the memory to be protected
  */
  MPU_InitStruct.Enable = MPU_REGION_ENABLE;
  MPU_InitStruct.Number = MPU_REGION_NUMBER0;
  MPU_InitStruct.BaseAddress = 0x0;
  MPU_InitStruct.Size = MPU_REGION_SIZE_4GB;
  MPU_InitStruct.SubRegionDisable = 0x0;
  MPU_InitStruct.TypeExtField = MPU_TEX_LEVEL1;
  MPU_InitStruct.AccessPermission = MPU_REGION_FULL_ACCESS;
  MPU_InitStruct.DisableExec = MPU_INSTRUCTION_ACCESS_ENABLE;
  MPU_InitStruct.IsShareable = MPU_ACCESS_NOT_SHAREABLE;
  MPU_InitStruct.IsCacheable = MPU_ACCESS_NOT_CACHEABLE;
  MPU_InitStruct.IsBufferable = MPU_ACCESS_NOT_BUFFERABLE;

  HAL_MPU_ConfigRegion(&MPU_InitStruct);

  /** Initializes and configures the Region and the memory to be protected
  */
  MPU_InitStruct.Number = MPU_REGION_NUMBER1;
  MPU_InitStruct.BaseAddress = 0x90000000;
  MPU_InitStruct.Size = MPU_REGION_SIZE_256MB;
  MPU_InitStruct.TypeExtField = MPU_TEX_LEVEL2;
  MPU_InitStruct.DisableExec = MPU_INSTRUCTION_ACCESS_DISABLE;

  HAL_MPU_ConfigRegion(&MPU_InitStruct);

  /** Initializes and configures the Region and the memory to be protected
  */
  MPU_InitStruct.Number = MPU_REGION_NUMBER2;
  MPU_InitStruct.BaseAddress = 0x0;
  MPU_InitStruct.Size = MPU_REGION_SIZE_512MB;
  MPU_InitStruct.TypeExtField = MPU_TEX_LEVEL0;
  MPU_InitStruct.DisableExec = MPU_INSTRUCTION_ACCESS_ENABLE;
  MPU_InitStruct.IsCacheable = MPU_ACCESS_CACHEABLE;

  HAL_MPU_ConfigRegion(&MPU_InitStruct);

  /** Initializes and configures the Region and the memory to be protected
  */
  MPU_InitStruct.Number = MPU_REGION_NUMBER3;
  MPU_InitStruct.Size = MPU_REGION_SIZE_64KB;
  MPU_InitStruct.AccessPermission = MPU_REGION_PRIV_RO_URO;

  HAL_MPU_ConfigRegion(&MPU_InitStruct);

  /** Initializes and configures the Region and the memory to be protected
  */
  MPU_InitStruct.Number = MPU_REGION_NUMBER4;
  MPU_InitStruct.Size = MPU_REGION_SIZE_4KB;
  MPU_InitStruct.AccessPermission = MPU_REGION_NO_ACCESS;
  MPU_InitStruct.DisableExec = MPU_INSTRUCTION_ACCESS_DISABLE;
  MPU_InitStruct.IsCacheable = MPU_ACCESS_NOT_CACHEABLE;

  HAL_MPU_ConfigRegion(&MPU_InitStruct);

  /** Initializes and configures the Region and the memory to be protected
  */
  MPU_InitStruct.Number = MPU_REGION_NUMBER5;
  MPU_InitStruct.BaseAddress = 0x40000000;
  MPU_InitStruct.Size = MPU_REGION_SIZE_512MB;
  MPU_InitStruct.TypeExtField = MPU_TEX_LEVEL2;
  MPU_InitStruct.AccessPermission = MPU_REGION_FULL_ACCESS;

  HAL_MPU_ConfigRegion(&MPU_InitStruct);
  /* Enables the MPU */
  HAL_MPU_Enable(MPU_PRIVILEGED_DEFAULT);

}

void Error_Handler(void)
{
  __disable_irq();
  while (1)
  {
  }
}
